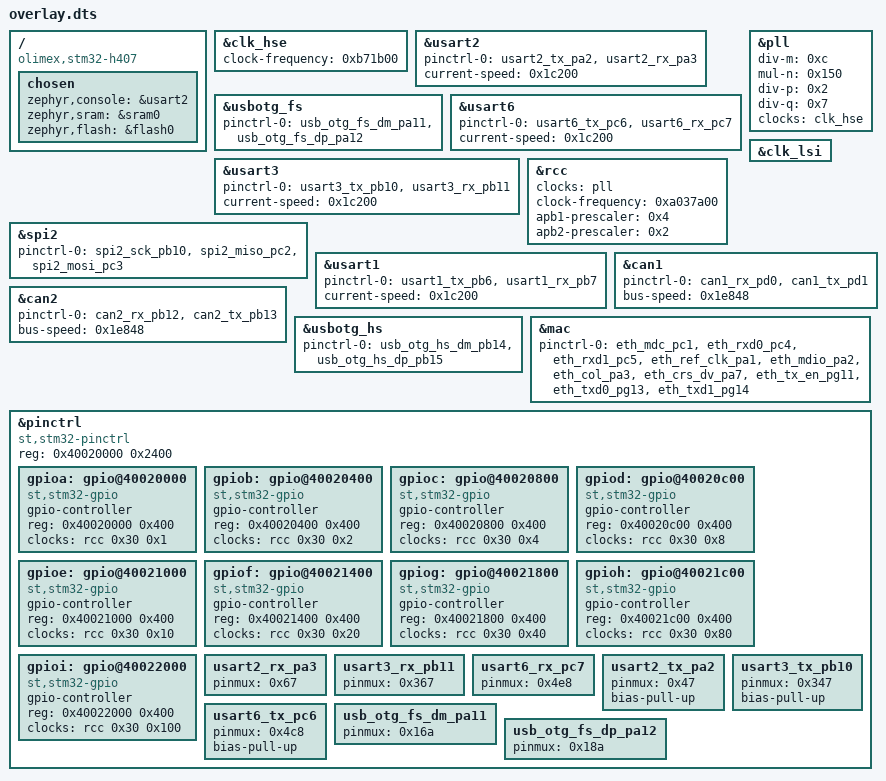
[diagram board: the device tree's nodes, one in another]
/ {
	compatible = "olimex,stm32-h407";
	chosen {
		zephyr,console = &usart2;
		zephyr,sram = &sram0;
		zephyr,flash = &flash0;
	};
};
&clk_hse{
	status = "okay";
	clock-frequency = < 0xb71b00 >;
};
&usart2{
	status = "okay";
	pinctrl-0 = < &usart2_tx_pa2 &usart2_rx_pa3 >;
	pinctrl-names = "default";
	current-speed = < 0x1c200 >;
};
&usbotg_fs{
	pinctrl-0 = < &usb_otg_fs_dm_pa11 &usb_otg_fs_dp_pa12 >;
	pinctrl-names = "default";
};
&usart6{
	status = "okay";
	pinctrl-0 = < &usart6_tx_pc6 &usart6_rx_pc7 >;
	pinctrl-names = "default";
	current-speed = < 0x1c200 >;
};
&pll{
	status = "okay";
	div-m = < 0xc >;
	mul-n = < 0x150 >;
	div-p = < 0x2 >;
	div-q = < 0x7 >;
	clocks = < &clk_hse >;
};
&usart3{
	status = "okay";
	pinctrl-0 = < &usart3_tx_pb10 &usart3_rx_pb11 >;
	pinctrl-names = "default";
	current-speed = < 0x1c200 >;
};
&rcc{
	clocks = < &pll >;
	clock-frequency = < 0xa037a00 >;
	apb1-prescaler = < 0x4 >;
	apb2-prescaler = < 0x2 >;
};
&clk_lsi{
	status = "okay";
};
&spi2{
	status = "okay";
	pinctrl-0 = < &spi2_sck_pb10 &spi2_miso_pc2 &spi2_mosi_pc3 >;
	pinctrl-names = "default";
};
&usart1{
	status = "okay";
	pinctrl-0 = < &usart1_tx_pb6 &usart1_rx_pb7 >;
	pinctrl-names = "default";
	current-speed = < 0x1c200 >;
};
&can1{
	pinctrl-0 = < &can1_rx_pd0 &can1_tx_pd1 >;
	pinctrl-names = "default";
	bus-speed = < 0x1e848 >;
};
&can2{
	status = "okay";
	pinctrl-0 = < &can2_rx_pb12 &can2_tx_pb13 >;
	pinctrl-names = "default";
	bus-speed = < 0x1e848 >;
};
&usbotg_hs{
	status = "okay";
	pinctrl-0 = < &usb_otg_hs_dm_pb14 &usb_otg_hs_dp_pb15 >;
	pinctrl-names = "default";
};
&mac{
	status = "okay";
	pinctrl-0 = < &eth_mdc_pc1 &eth_rxd0_pc4 &eth_rxd1_pc5 &eth_ref_clk_pa1 &eth_mdio_pa2 &eth_col_pa3 &eth_crs_dv_pa7 &eth_tx_en_pg11 &eth_txd0_pg13 &eth_txd1_pg14 >;
	pinctrl-names = "default";
};
&pinctrl{
	compatible = "st,stm32-pinctrl";
	#address-cells = < 0x1 >;
	#size-cells = < 0x1 >;
	reg = < 0x40020000 0x2400 >;
	gpioa: gpio@40020000 {
		compatible = "st,stm32-gpio";
		gpio-controller;
		#gpio-cells = < 0x2 >;
		reg = < 0x40020000 0x400 >;
		clocks = < &rcc 0x30 0x1 >;
	};
	gpiob: gpio@40020400 {
		compatible = "st,stm32-gpio";
		gpio-controller;
		#gpio-cells = < 0x2 >;
		reg = < 0x40020400 0x400 >;
		clocks = < &rcc 0x30 0x2 >;
	};
	gpioc: gpio@40020800 {
		compatible = "st,stm32-gpio";
		gpio-controller;
		#gpio-cells = < 0x2 >;
		reg = < 0x40020800 0x400 >;
		clocks = < &rcc 0x30 0x4 >;
	};
	gpiod: gpio@40020c00 {
		compatible = "st,stm32-gpio";
		gpio-controller;
		#gpio-cells = < 0x2 >;
		reg = < 0x40020c00 0x400 >;
		clocks = < &rcc 0x30 0x8 >;
	};
	gpioe: gpio@40021000 {
		compatible = "st,stm32-gpio";
		gpio-controller;
		#gpio-cells = < 0x2 >;
		reg = < 0x40021000 0x400 >;
		clocks = < &rcc 0x30 0x10 >;
	};
	gpiof: gpio@40021400 {
		compatible = "st,stm32-gpio";
		gpio-controller;
		#gpio-cells = < 0x2 >;
		reg = < 0x40021400 0x400 >;
		clocks = < &rcc 0x30 0x20 >;
	};
	gpiog: gpio@40021800 {
		compatible = "st,stm32-gpio";
		gpio-controller;
		#gpio-cells = < 0x2 >;
		reg = < 0x40021800 0x400 >;
		clocks = < &rcc 0x30 0x40 >;
	};
	gpioh: gpio@40021c00 {
		compatible = "st,stm32-gpio";
		gpio-controller;
		#gpio-cells = < 0x2 >;
		reg = < 0x40021c00 0x400 >;
		clocks = < &rcc 0x30 0x80 >;
	};
	gpioi: gpio@40022000 {
		compatible = "st,stm32-gpio";
		gpio-controller;
		#gpio-cells = < 0x2 >;
		reg = < 0x40022000 0x400 >;
		clocks = < &rcc 0x30 0x100 >;
	};
	usart2_rx_pa3: usart2_rx_pa3 {
		pinmux = < 0x67 >;
	};
	usart3_rx_pb11: usart3_rx_pb11 {
		pinmux = < 0x367 >;
	};
	usart6_rx_pc7: usart6_rx_pc7 {
		pinmux = < 0x4e8 >;
	};
	usart2_tx_pa2: usart2_tx_pa2 {
		pinmux = < 0x47 >;
		bias-pull-up;
	};
	usart3_tx_pb10: usart3_tx_pb10 {
		pinmux = < 0x347 >;
		bias-pull-up;
	};
	usart6_tx_pc6: usart6_tx_pc6 {
		pinmux = < 0x4c8 >;
		bias-pull-up;
	};
	usb_otg_fs_dm_pa11: usb_otg_fs_dm_pa11 {
		pinmux = < 0x16a >;
	};
	usb_otg_fs_dp_pa12: usb_otg_fs_dp_pa12 {
		pinmux = < 0x18a >;
	};
};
